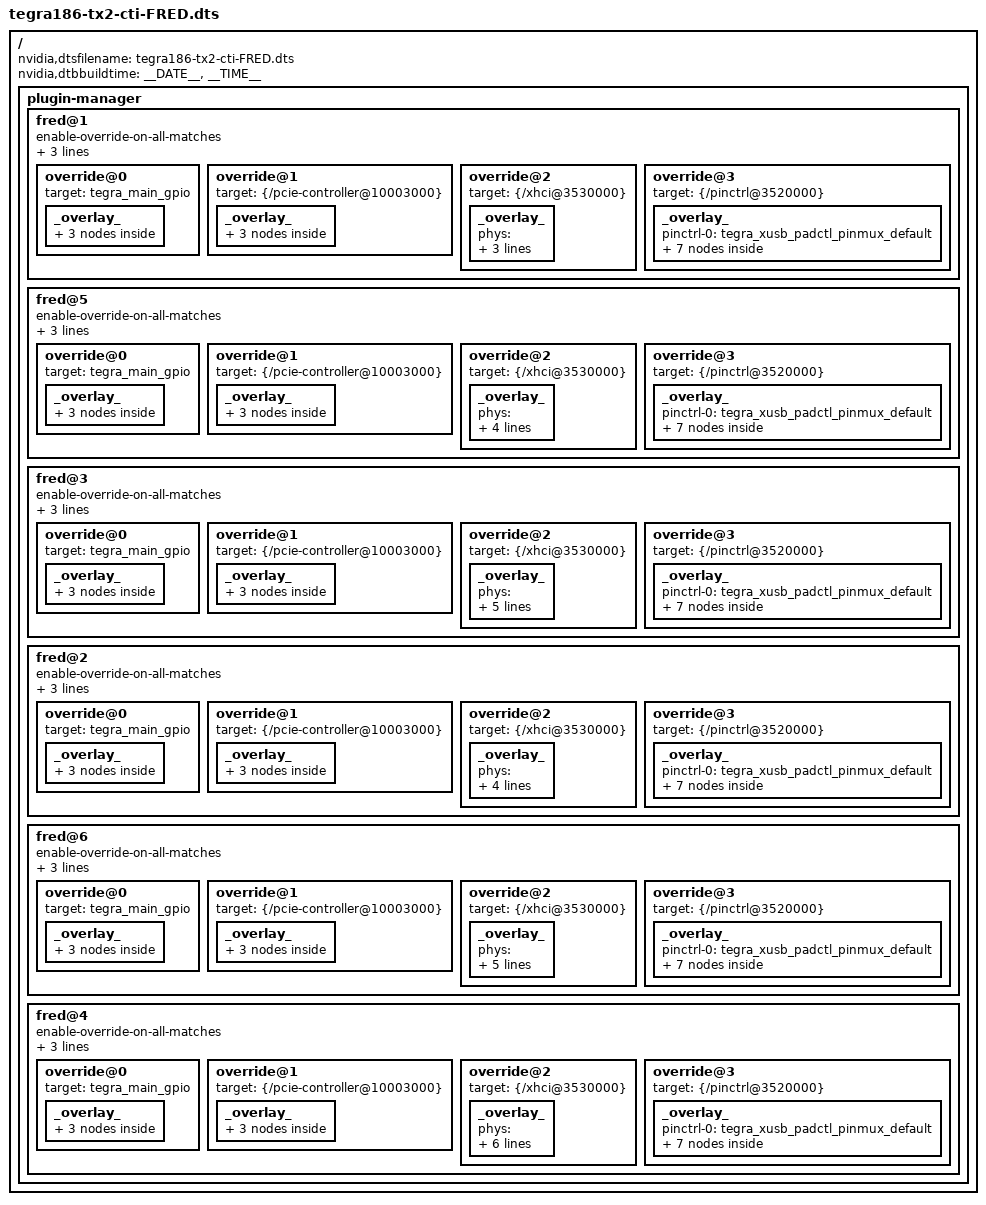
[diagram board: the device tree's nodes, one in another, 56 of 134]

/*CTI Universal platform, "Fred Flintstone" */

#include "tegra186-tx2-cti-base.dts"
//#include <t18x-common-platforms/tegra186-tx2-cti-camera-ASG001.dtsi>

/{
    nvidia,dtsfilename = "tegra186-tx2-cti-FRED.dts";
    nvidia,dtbbuildtime = __DATE__, __TIME__;



/*************************************************************************************************/
/*******************These plugins handle all the pcie/usb3 based on the odm data******************/ 
    plugin-manager{
        /*Config 1*/
        fred@1{  
            enable-override-on-all-matches;
            odm-data = "enable-pcie-on-uphy-lane1", "enable-pcie-on-uphy-lane2", "enable-pcie-on-uphy-lane0";  
            override@0{
                target = <&tegra_main_gpio>;
                _overlay_ {
                    e3325_sdio_rst {
                        status = "disabled";
                    };
                    e3325_lane0_mux {
                        status = "disabled";
                    };

                    pcie0_lane2_mux {
                         status = "okay";
                    };

                };      
            };
            override@1{
               target = <&{/pcie-controller@10003000}>;

                    _overlay_ {
                        status = "okay";
                        pci@1,0 {
                            nvidia,num-lanes = <4>;
                            status = "okay";

                        };
                        pci@2,0 {
                            nvidia,num-lanes = <0>;
                            status = "disabled";
                        };
                        pci@3,0 {
                            nvidia,num-lanes = <1>;
                            status = "okay";
                        };
                    };

                };
            override@2{

                target = <&{/xhci@3530000}>;
                    _overlay_ {
                    status = "okay";
                    phys = <&tegra_xusb_padctl TEGRA_PADCTL_PHY_UTMI_P(0)>,
                        <&tegra_xusb_padctl TEGRA_PADCTL_PHY_UTMI_P(1)>,
                        <&tegra_xusb_padctl TEGRA_PADCTL_PHY_UTMI_P(2)>;
                    phy-names = "utmi-0", "utmi-1", "utmi-2";
                };
            }; 

            override@3{ 
                target = <&{/pinctrl@3520000}>;

                _overlay_ {
                   status = "okay";
                    pinctrl-0 = <&tegra_xusb_padctl_pinmux_default>;
                    pinctrl-names = "default";
                    pinmux {

                        usb2-port0 {
                            nvidia,lanes = "otg-0";
                            nvidia,function = "xusb";
                            nvidia,port-cap = <TEGRA_PADCTL_PORT_OTG_CAP>;
                            nvidia,oc-pin = <0>;
                            status = "okay";
                        };
                        usb2-port1 {
                            nvidia,lanes = "otg-1";
                            nvidia,function = "xusb";
                            nvidia,port-cap = <TEGRA_PADCTL_PORT_HOST_ONLY>;
                            nvidia,oc-pin = <1>;
                            status = "okay";
                        };
                        usb2-port2 {
                            nvidia,lanes = "otg-2";
                            nvidia,function = "xusb";
                            nvidia,port-cap = <TEGRA_PADCTL_PORT_HOST_ONLY>;
                            status = "okay";
                        };
                        usb3-port0 {
                            nvidia,lanes = "usb3-0";
                            nvidia,port-cap = <TEGRA_PADCTL_PORT_HOST_ONLY>;
                            status = "disabled";
                        };
                        usb3-port1 {
                            nvidia,lanes = "usb3-1";
                            nvidia,port-cap = <TEGRA_PADCTL_PORT_HOST_ONLY>;
                            status = "disabled";
                        };
                        usb3-port2 {
                            nvidia,lanes = "usb3-2";
                            nvidia,port-cap = <TEGRA_PADCTL_PORT_HOST_ONLY>;
                            status = "disabled";
                        };
                    };
                };
            };
        };

        /*Config 5*/
        fred@5{ 
            enable-override-on-all-matches;
            odm-data = "enable-xusb-on-uphy-lane1", "enable-pcie-on-uphy-lane2", "enable-pcie-on-uphy-lane0"; 
            override@0{
                target = <&tegra_main_gpio>;
                _overlay_ {
                    e3325_sdio_rst {
                        status = "disabled";
                    };
                    e3325_lane0_mux {
                        status = "disabled";
                    };

                    pcie0_lane2_mux {
                         status = "okay";
                    };

                };      
            };
            override@1{
               target = <&{/pcie-controller@10003000}>;

                    _overlay_ {
                        status = "okay";
                        pci@1,0 {
                            nvidia,num-lanes = <2>;
                            status = "okay";

                        };
                        pci@2,0 {
                            nvidia,num-lanes = <1>;
                            status = "okay";
                        };
                        pci@3,0 {
                            nvidia,num-lanes = <1>;
                            status = "okay";
                        };
                    };

                };
            override@2{

                target = <&{/xhci@3530000}>;
                    _overlay_ {
                    status = "okay";
                    phys = <&tegra_xusb_padctl TEGRA_PADCTL_PHY_UTMI_P(0)>,
                        <&tegra_xusb_padctl TEGRA_PADCTL_PHY_UTMI_P(1)>,
                        <&tegra_xusb_padctl TEGRA_PADCTL_PHY_UTMI_P(2)>,
                        <&tegra_xusb_padctl TEGRA_PADCTL_PHY_USB3_P(1)>;
                    phy-names = "utmi-0", "utmi-1", "utmi-2", "usb3-1";
                };
            }; 

            override@3{ 
                target = <&{/pinctrl@3520000}>;

                _overlay_ {
                   status = "okay";
                    pinctrl-0 = <&tegra_xusb_padctl_pinmux_default>;
                    pinctrl-names = "default";
                    pinmux {

                        usb2-port0 {
                            nvidia,lanes = "otg-0";
                            nvidia,function = "xusb";
                            nvidia,port-cap = <TEGRA_PADCTL_PORT_OTG_CAP>;
                            nvidia,oc-pin = <0>;
                            status = "okay";
                        };
                        usb2-port1 {
                            nvidia,lanes = "otg-1";
                            nvidia,function = "xusb";
                            nvidia,port-cap = <TEGRA_PADCTL_PORT_HOST_ONLY>;
                            nvidia,oc-pin = <1>;
                            status = "okay";
                        };
                        usb2-port2 {
                            nvidia,lanes = "otg-2";
                            nvidia,function = "xusb";
                            nvidia,port-cap = <TEGRA_PADCTL_PORT_HOST_ONLY>;
                            status = "okay";
                        };
                        usb3-port0 {
                            nvidia,lanes = "usb3-0";
                            nvidia,port-cap = <TEGRA_PADCTL_PORT_HOST_ONLY>;
                            status = "disabled";
                        };
                        usb3-port1 {
                            nvidia,lanes = "usb3-1";
                            nvidia,port-cap = <TEGRA_PADCTL_PORT_HOST_ONLY>;
                            status = "okay";
                        };
                        usb3-port2 {
                            nvidia,lanes = "usb3-2";
                            nvidia,port-cap = <TEGRA_PADCTL_PORT_HOST_ONLY>;
                            status = "disabled";
                        };
                    };
                };
            };
        };

        /*Config 3*/
        fred@3{
            enable-override-on-all-matches;
            odm-data = "enable-xusb-on-uphy-lane1", "enable-xusb-on-uphy-lane2", "enable-pcie-on-uphy-lane0";  
            override@0{
                target = <&tegra_main_gpio>;
                _overlay_ {
                    e3325_sdio_rst {
                        status = "disabled";
                    };
                    e3325_lane0_mux {
                        status = "disabled";
                    };

                    pcie0_lane2_mux {
                         status = "okay";
                    };

                };      
            };


            override@1{
               target = <&{/pcie-controller@10003000}>;

                    _overlay_ {
                        status = "okay";
                        pci@1,0 {
                            nvidia,num-lanes = <1>;
                            status = "okay";

                        };
                        pci@2,0 {
                            nvidia,num-lanes = <0>;
                            status = "disabled";    //this should be okay but it is not working in the driver
                        };
                        pci@3,0 {
                            nvidia,num-lanes = <1>;
                            status = "okay";
                        };
                    };

                };
            override@2{

                target = <&{/xhci@3530000}>;
                    _overlay_ {
                    status = "okay";
                    phys = <&tegra_xusb_padctl TEGRA_PADCTL_PHY_UTMI_P(0)>,
                        <&tegra_xusb_padctl TEGRA_PADCTL_PHY_UTMI_P(1)>,
                        <&tegra_xusb_padctl TEGRA_PADCTL_PHY_UTMI_P(2)>,
                        <&tegra_xusb_padctl TEGRA_PADCTL_PHY_USB3_P(1)>,
                        <&tegra_xusb_padctl TEGRA_PADCTL_PHY_USB3_P(2)>;
                    phy-names = "utmi-0", "utmi-1", "utmi-2", "usb3-1", "usb3-2";
                };
            }; 

            override@3{ 
                target = <&{/pinctrl@3520000}>;

                _overlay_ {
                   status = "okay";
                    pinctrl-0 = <&tegra_xusb_padctl_pinmux_default>;
                    pinctrl-names = "default";
                    pinmux {

                        usb2-port0 {
                            nvidia,lanes = "otg-0";
                            nvidia,function = "xusb";
                            nvidia,port-cap = <TEGRA_PADCTL_PORT_OTG_CAP>;
                            nvidia,oc-pin = <0>;
                            status = "okay";
                        };
                        usb2-port1 {
                            nvidia,lanes = "otg-1";
                            nvidia,function = "xusb";
                            nvidia,port-cap = <TEGRA_PADCTL_PORT_HOST_ONLY>;
                            nvidia,oc-pin = <1>;
                            status = "okay";
                        };
                        usb2-port2 {
                            nvidia,lanes = "otg-2";
                            nvidia,function = "xusb";
                            nvidia,port-cap = <TEGRA_PADCTL_PORT_HOST_ONLY>;
                            status = "okay";
                        };
                        usb3-port0 {
                            nvidia,lanes = "usb3-0";
                            nvidia,port-cap = <TEGRA_PADCTL_PORT_HOST_ONLY>;
                            status = "disabled";
                        };
                        usb3-port1 {
                            nvidia,lanes = "usb3-1";
                            nvidia,port-cap = <TEGRA_PADCTL_PORT_HOST_ONLY>;
                            status = "okay";
                        };
                        usb3-port2 {
                            nvidia,lanes = "usb3-2";
                            nvidia,port-cap = <TEGRA_PADCTL_PORT_HOST_ONLY>;
                            status = "okay";
                        };
                    };
                };
            };

        };

        /*Config 2*/
        fred@2{     
            enable-override-on-all-matches;
            odm-data = "enable-pcie-on-uphy-lane1", "enable-pcie-on-uphy-lane2", "enable-xusb-on-uphy-lane0";     
            override@0{
                target = <&tegra_main_gpio>;
                _overlay_ {
                    e3325_sdio_rst {
                        status = "okay";
                    };
                    e3325_lane0_mux {
                        status = "okay";
                    };

                    pcie0_lane2_mux {
                         status = "disabled";
                    };

                };      
            };
            override@1{
               target = <&{/pcie-controller@10003000}>;

                    _overlay_ {
                        status = "okay";
                        pci@1,0 {
                            nvidia,num-lanes = <4>;
                            status = "okay";

                        };
                        pci@2,0 {
                            nvidia,num-lanes = <0>;
                            status = "disabled";
                        };
                        pci@3,0 {
                            nvidia,num-lanes = <1>;
                            status = "disabled";
                        };
                    };

                };
            override@2{

                target = <&{/xhci@3530000}>;
                    _overlay_ {
                    status = "okay";
                    phys = <&tegra_xusb_padctl TEGRA_PADCTL_PHY_UTMI_P(0)>,
                        <&tegra_xusb_padctl TEGRA_PADCTL_PHY_UTMI_P(1)>,
                        <&tegra_xusb_padctl TEGRA_PADCTL_PHY_UTMI_P(2)>,
                        <&tegra_xusb_padctl TEGRA_PADCTL_PHY_USB3_P(0)>;
                    phy-names = "utmi-0", "utmi-1", "utmi-2", "usb3-0";
                };
            }; 

            override@3{ 
                target = <&{/pinctrl@3520000}>;

                _overlay_ {
                   status = "okay";
                    pinctrl-0 = <&tegra_xusb_padctl_pinmux_default>;
                    pinctrl-names = "default";
                    pinmux {

                        usb2-port0 {
                            nvidia,lanes = "otg-0";
                            nvidia,function = "xusb";
                            nvidia,port-cap = <TEGRA_PADCTL_PORT_OTG_CAP>;
                            nvidia,oc-pin = <0>;
                            status = "okay";
                        };
                        usb2-port1 {
                            nvidia,lanes = "otg-1";
                            nvidia,function = "xusb";
                            nvidia,port-cap = <TEGRA_PADCTL_PORT_HOST_ONLY>;
                            nvidia,oc-pin = <1>;
                            status = "okay";
                        };
                        usb2-port2 {
                            nvidia,lanes = "otg-2";
                            nvidia,function = "xusb";
                            nvidia,port-cap = <TEGRA_PADCTL_PORT_HOST_ONLY>;
                            status = "okay";
                        };
                        usb3-port0 {
                            nvidia,lanes = "usb3-0";
                            nvidia,port-cap = <TEGRA_PADCTL_PORT_HOST_ONLY>;
                            status = "okay";
                        };
                        usb3-port1 {
                            nvidia,lanes = "usb3-1";
                            nvidia,port-cap = <TEGRA_PADCTL_PORT_HOST_ONLY>;
                            status = "disabled";
                        };
                        usb3-port2 {
                            nvidia,lanes = "usb3-2";
                            nvidia,port-cap = <TEGRA_PADCTL_PORT_HOST_ONLY>;
                            status = "disabled";
                        };
                    };
                };
            };

        };

        /*Config 6*/
        fred@6{
            enable-override-on-all-matches;
            odm-data = "enable-xusb-on-uphy-lane1", "enable-pcie-on-uphy-lane2", "enable-xusb-on-uphy-lane0";     
            override@0{
                target = <&tegra_main_gpio>;
                _overlay_ {
                    e3325_sdio_rst {
                        status = "okay";
                    };
                    e3325_lane0_mux {
                        status = "okay";
                    };

                    pcie0_lane2_mux {
                         status = "disabled";
                    };

                };      
            };

            override@1{
               target = <&{/pcie-controller@10003000}>;

                    _overlay_ {
                        status = "okay";
                        pci@1,0 {
                            nvidia,num-lanes = <2>;
                            status = "okay";

                        };
                        pci@2,0 {
                            nvidia,num-lanes = <1>;
                            status = "okay";
                        };
                        pci@3,0 {
                            nvidia,num-lanes = <1>;
                            status = "disabled";
                        };
                    };

                };
            override@2{

                target = <&{/xhci@3530000}>;
                    _overlay_ {
                    status = "okay";
                    phys = <&tegra_xusb_padctl TEGRA_PADCTL_PHY_UTMI_P(0)>,
                        <&tegra_xusb_padctl TEGRA_PADCTL_PHY_UTMI_P(1)>,
                        <&tegra_xusb_padctl TEGRA_PADCTL_PHY_UTMI_P(2)>,
                        <&tegra_xusb_padctl TEGRA_PADCTL_PHY_USB3_P(0)>,
                        <&tegra_xusb_padctl TEGRA_PADCTL_PHY_USB3_P(1)>;
                    phy-names = "utmi-0", "utmi-1", "utmi-2", "usb3-0", "usb3-1";
                };
            }; 

            override@3{ 
                target = <&{/pinctrl@3520000}>;

                _overlay_ {
                   status = "okay";
                    pinctrl-0 = <&tegra_xusb_padctl_pinmux_default>;
                    pinctrl-names = "default";
                    pinmux {

                        usb2-port0 {
                            nvidia,lanes = "otg-0";
                            nvidia,function = "xusb";
                            nvidia,port-cap = <TEGRA_PADCTL_PORT_OTG_CAP>;
                            nvidia,oc-pin = <0>;
                            status = "okay";
                        };
                        usb2-port1 {
                            nvidia,lanes = "otg-1";
                            nvidia,function = "xusb";
                            nvidia,port-cap = <TEGRA_PADCTL_PORT_HOST_ONLY>;
                            nvidia,oc-pin = <1>;
                            status = "okay";
                        };
                        usb2-port2 {
                            nvidia,lanes = "otg-2";
                            nvidia,function = "xusb";
                            nvidia,port-cap = <TEGRA_PADCTL_PORT_HOST_ONLY>;
                            status = "okay";
                        };
                        usb3-port0 {
                            nvidia,lanes = "usb3-0";
                            nvidia,port-cap = <TEGRA_PADCTL_PORT_HOST_ONLY>;
                            status = "okay";
                        };
                        usb3-port1 {
                            nvidia,lanes = "usb3-1";
                            nvidia,port-cap = <TEGRA_PADCTL_PORT_HOST_ONLY>;
                            status = "okay";
                        };
                        usb3-port2 {
                            nvidia,lanes = "usb3-2";
                            nvidia,port-cap = <TEGRA_PADCTL_PORT_HOST_ONLY>;
                            status = "disabled";
                        };
                    };
                };
            };
        };

        /*Config 4*/
        fred@4{ 
            enable-override-on-all-matches;
            odm-data = "enable-xusb-on-uphy-lane1", "enable-xusb-on-uphy-lane2", "enable-xusb-on-uphy-lane0"; 
            override@0{
                target = <&tegra_main_gpio>;
                _overlay_ {
                    e3325_sdio_rst {
                        status = "okay";
                    };
                    e3325_lane0_mux {
                        status = "okay";
                    };

                    pcie0_lane2_mux {
                         status = "disabled";
                    };

                };      
            };

            override@1{
               target = <&{/pcie-controller@10003000}>;

                    _overlay_ {
                        status = "okay";
                        pci@1,0 {
                            nvidia,num-lanes = <1>;
                            status = "okay";

                        };
                        pci@2,0 {
                            nvidia,num-lanes = <1>;
                            status = "okay";
                        };
                        pci@3,0 {
                            nvidia,num-lanes = <1>;
                            status = "disabled";
                        };
                    };

                };
            override@2{

                target = <&{/xhci@3530000}>;
                    _overlay_ {
                    status = "okay";
                    phys = <&tegra_xusb_padctl TEGRA_PADCTL_PHY_UTMI_P(0)>,
                        <&tegra_xusb_padctl TEGRA_PADCTL_PHY_UTMI_P(1)>,
                        <&tegra_xusb_padctl TEGRA_PADCTL_PHY_UTMI_P(2)>,
                        <&tegra_xusb_padctl TEGRA_PADCTL_PHY_USB3_P(0)>,
                        <&tegra_xusb_padctl TEGRA_PADCTL_PHY_USB3_P(1)>,
                        <&tegra_xusb_padctl TEGRA_PADCTL_PHY_USB3_P(2)>;
                    phy-names = "utmi-0", "utmi-1", "utmi-2", "usb3-0", "usb3-1", "usb3-2";
                };
            }; 

            override@3{ 
                target = <&{/pinctrl@3520000}>;

                _overlay_ {
                   status = "okay";
                    pinctrl-0 = <&tegra_xusb_padctl_pinmux_default>;
                    pinctrl-names = "default";
                    pinmux {

                        usb2-port0 {
                            nvidia,lanes = "otg-0";
                            nvidia,function = "xusb";
                            nvidia,port-cap = <TEGRA_PADCTL_PORT_OTG_CAP>;
                            nvidia,oc-pin = <0>;
                            status = "okay";
                        };
                        usb2-port1 {
                            nvidia,lanes = "otg-1";
                            nvidia,function = "xusb";
                            nvidia,port-cap = <TEGRA_PADCTL_PORT_HOST_ONLY>;
                            nvidia,oc-pin = <1>;
                            status = "okay";
                        };
                        usb2-port2 {
                            nvidia,lanes = "otg-2";
                            nvidia,function = "xusb";
                            nvidia,port-cap = <TEGRA_PADCTL_PORT_HOST_ONLY>;
                            status = "okay";
                        };
                        usb3-port0 {
                            nvidia,lanes = "usb3-0";
                            nvidia,port-cap = <TEGRA_PADCTL_PORT_HOST_ONLY>;
                            status = "okay";
                        };
                        usb3-port1 {
                            nvidia,lanes = "usb3-1";
                            nvidia,port-cap = <TEGRA_PADCTL_PORT_HOST_ONLY>;
                            status = "okay";
                        };
                        usb3-port2 {
                            nvidia,lanes = "usb3-2";
                            nvidia,port-cap = <TEGRA_PADCTL_PORT_HOST_ONLY>;
                            status = "okay";
                        };
                    };
                };
            };
        };

    };

};
